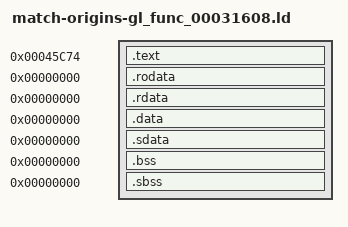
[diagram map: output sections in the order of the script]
/* Standard linker bindings; original USO identity is independently audited. */
SECTIONS {
 .text 0x45c74 : SUBALIGN(4) { *(.text) *(.text.*) }
 .rodata 0x0 : SUBALIGN(4) { *(.rodata) *(.rodata.*) }
 .rdata 0x0 : SUBALIGN(4) { *(.rdata) *(.rdata.*) }
 .data 0x0 : SUBALIGN(4) { *(.data) *(.data.*) }
 .sdata 0x0 : SUBALIGN(4) { *(.sdata) *(.sdata.*) }
 .bss 0x0 : SUBALIGN(4) { *(.bss) *(.bss.*) }
 .sbss 0x0 : SUBALIGN(4) { *(.sbss) *(.sbss.*) }
 /DISCARD/ : { *(.mdebug) *(.reginfo) *(.pdr) *(.comment) *(.MIPS.abiflags) *(.options) }
}
gl_31608_gate = 0x0;
gl_31608_set = 0x45dc0;
gl_31608_state = 0x0;
gl_31608_storage = 0x0;
